# DISPC_L4_PER register map
Vendor: Texas Instruments
Registers are 32-bit, access per field, reset 0x0 unless marked. A register's access mark holds for its fields unless they carry their own. Offsets are as the file gives them; [hi:lo] are bit positions; {n}, {i} and the like mark numbered series; 'fields as' and 'values as' point back to an identical list.

## DISPC_L4_PER (part 5 of 5)
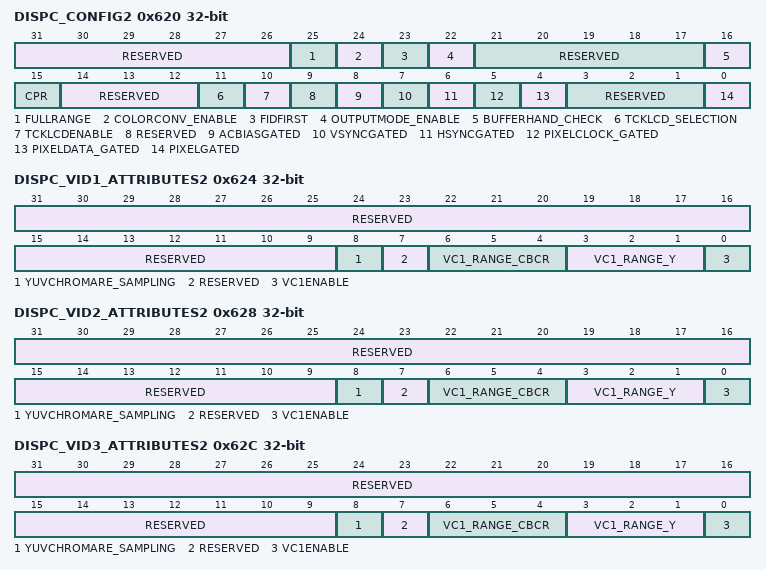
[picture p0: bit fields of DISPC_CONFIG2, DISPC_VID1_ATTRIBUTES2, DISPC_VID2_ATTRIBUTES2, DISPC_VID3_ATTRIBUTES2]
0x620 DISPC_CONFIG2 — The control register configures the Display Controller module for the secondary LCD output. Shadow register, updated on VFP start period of secondary LCD or EVSYNC
  [31:26] RESERVED ro — Write 0s for future compatibility. Reads return 0.
  [25] FULLRANGE rw — Color Space Conversion full range setting.
    0=Limited range selected; 1=Full range selected
  [24] COLORCONV_ENABLE rw — Enable the color space conversion. It shall be reset when CPR bit field is set to 0x1.
    0=Disable Color Space Conversion RGB to YUV; 1=Enable Color Space Conversion RGB to YUV
  [23] FIDFIRST rw — Selects the first field to output in case of interlace mode. In case of progressive mode, the value is not used.
    0=First field is even; 1=Odd field is first
  [22] OUTPUTMODE_ENABLE rw — Selects between progressive and interlace mode for the secondary LCD output.
    0=Progressive mode selected; 1=Interlace mode selected
  [21:17] RESERVED ro — Write 0s for future compatibility. Reads return 0.
  [16] BUFFERHAND_CHECK rw — Controls the handcheck between DMA buffer and STALL signal in order to prevent from underflow. The bit shall be set to 0 when the module is not in STALL mode. (secondary LCD output)
    0=Only the STALL signal (generated by RFBI or DSI2 depending on which IP uses the LCD output) is used regardless of the DMA buffer fullness information in order to provide data to the RFBI or DS2 module; 1=The STALL signal (generated by RFBI or DSI2 depending on which IP uses the LCD output) is used in combination with the DMA buffer fullness information in order to provide data to the RFBI or DSI2 module only when it does not generated buffer underflow
  [15] CPR rw — Color Phase Rotation Control secondary LCD output). It shall be reset when ColorConvEnable bit field is set to 1. wr: VFP start period of secondary LCD output
    0=Color Phase Rotation Disabled; 1=Color Phase Rotation Enabled
  [14:12] RESERVED ro — Write 0s for future compatibility. Reads return 0.
  [11] TCKLCD_SELECTION rw — Transparency Color Key Selection (secondary LCD output) wr: VFP start period of secondary LCD output
    0=Destination transparency color key selected; 1=Source transparency color key selected
  [10] TCKLCDENABLE rw — Transparency Color Key Enabled (secondary LCD output) wr: VFP start period of secondary LCD output
    0=Disable the transparency color key for the LCD; 1=Enable the transparency color key for the LCD
  [9] RESERVED ro — Write 0s for future compatibility. Reads return 0.
  [8] ACBIASGATED rw — ACBias Gated Enabled (secondary LCD output) wr: VFP start period of secondary LCD output
    0=AcBias Gated Disabled; 1=AcBias Gated Enabled
  [7] VSYNCGATED rw — VSYNC Gated Enabled (secondary LCD output) wr: VFP start period of secondary LCD output
    0=VSYNC Gated Disabled; 1=VSYNC Gated Enabled
  [6] HSYNCGATED rw — HSYNC Gated Enabled (secondary LCD output) wr: VFP start period of secondary LCD output
    0=HSYNC Gated Disabled; 1=HSYNC Gated Enabled
  [5] PIXELCLOCK_GATED rw — Pixel Clock Gated Enabled (secondary LCD output) wr: VFP start period of secondary LCD output
    0=Pixel Clock Gated Disabled; 1=Pixel Clock Gated Enabled
  [4] PIXELDATA_GATED rw — Pixel Data Gated Enabled (secondary LCD output) wr: VFP start period of secondary LCD output
    0=Pixel Data Gated Disabled; 1=Pixel Data Gated Enabled
  [3:1] RESERVED ro — Write 0s for future compatibility. Reads return 0.
  [0] PIXELGATED rw — Pixel Gated Enable (only for Active Matrix) (secondary LCD output) wr: VFP start period of secondary LCD output
    0=Pixel clock always toggles (only in Active Matrix mode); 1=Pixel clock only toggles when there is valid data to display. (only in Active Matrix mode)
0x624 DISPC_VID1_ATTRIBUTES2 — The register configures the attributes of the video window 1. Shadow register, updated on VFP start period of primary LCD or VFP start period of the secondary LCD or EVSYNC or when.GOWB is set to 1 by software and current WB frame is finished (no more data in the write-back pipeline). The synchronization event is defined based on the output using the pipeline: primary LCD, secondary LCD, TV output or write-back to the memory
  [31:9] RESERVED ro — Write 0s for future compatibility. Reads return 0.
  [8] YUVCHROMARE_SAMPLING rw — The YUV chrominance can be resampled using averaging of the adjacent chrominance samples, without using the polyphase filter for 4:2:2 input or can be calculated using the polyphase filter for 4:2:2/4:2:0. The polyphase filter is mandatory for the 4:2:0 format. This bit controls the order in which the processing is done on the video pipe.
    0=When input is 4:2:2, the missing chrominance samples are calculated by averaging the adjacent samples if. ROTATION=0 only. Other rotation configurations are not supported.; 1=For 4:2:2 (or 4:2:0), the missing chrominance samples are calculated by filtering the adjacent samples (5-tap polyphase filter). See, Configuration 2: Video Pipeline. All rotation configurations are supported.
  [7] RESERVED ro — Write 0s for future compatibility. Reads return 0.
  [6:4] VC1_RANGE_CBCR rw — Defines the VC-1 range value for the CbCr component from 0 to 7.
  [3:1] VC1_RANGE_Y rw — Defines the VC-1 range value for the Y component from 0 to 7.
  [0] VC1ENABLE rw — Enable/disable the VC-1 range mapping processing. The bit field is ignored if the format is not one of the supported YUV formats.
    0=VC-1 range mapping disabled; 1=VC-1 range mapping enabled
0x628 DISPC_VID2_ATTRIBUTES2 — The register configures the attributes of the video window 2. Shadow register, updated on VFP start period of primary LCD or VFP start period of the secondary LCD or EVSYNC or when.GOWB is set to 1 by software and current WB frame is finished (no more data in the write-back pipeline). The synchronization event is defined based on the output using the pipeline: primary LCD, secondary LCD, TV output or write-back to the memory
  [31:9] RESERVED ro — Write 0s for future compatibility. Reads return 0.
  [8] YUVCHROMARE_SAMPLING rw — The YUV chrominance can be resampled using averaging of the adjacent chrominance samples, without using the polyphase filter for 4:2:2 input or can be calculated using the polyphase filter for 4:2:2/4:2:0. The polyphase filter is mandatory for the 4:2:0 format. This bit controls the order in which the processing is done on the video pipe.
    0=When input is in 4:2:2, the missing chrominance samples are calculated by averaging the adjacent samples if. ROTATION=0 only. Other rotation configurations are not supported.; 1=For 4:2:2 (or 4:2:0), the missing chrominance samples are calculated by filtering the adjacent samples (5-tap polyphase filter). See, Configuration 2: Video Pipeline. All rotation configurations are supported.
  [7] RESERVED ro — Write 0s for future compatibility. Reads return 0.
  [6:4] VC1_RANGE_CBCR rw — Defines the VC-1 range value for the CbCr component from 0 to 7.
  [3:1] VC1_RANGE_Y rw — Defines the VC-1 range value for the Y component from 0 to 7.
  [0] VC1ENABLE rw — Enable/disable the VC-1 range mapping processing. The bit field is ignored if the format is not one of the supported YUV formats.
    0=VC-1 range mapping disabled; 1=VC-1 range mapping enabled
0x62C DISPC_VID3_ATTRIBUTES2 — The register configures the attributes of the video window 3. Shadow register, updated on VFP start period of primary LCD or VFP start period of the secondary LCD or EVSYNC or when.GOWB is set to 1 by software and current WB frame is finished (no more data in the write-back pipeline). The synchronization event is defined based on the output using the pipeline: primary LCD, secondary LCD, TV output or write-back to the memory
  fields as DISPC_VID2_ATTRIBUTES2
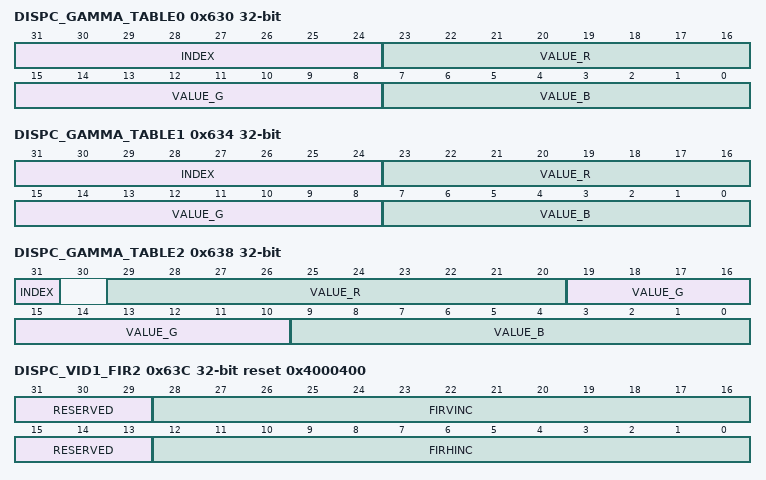
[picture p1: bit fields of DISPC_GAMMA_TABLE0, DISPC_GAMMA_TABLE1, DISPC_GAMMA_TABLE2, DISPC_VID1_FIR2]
0x630 DISPC_GAMMA_TABLE0 wo — The register configures the look up table used as color look up table for BITMAP formats (1-, 2-, 4, and 8-bpp) on the graphics pipeline or as gamma table on the primary LCD output.
  [31:24] INDEX — Defines the location in the table where the bit field VALUE is stored.
  [23:16] VALUE_R — 8-bit value used to defined the value to store at the location in the table defined by the bit field INDEX.
  [15:8] VALUE_G — 8-bit value used to defined the value to store at the location in the table defined by the bit field INDEX.
  [7:0] VALUE_B — 8-bit value used to defined the value to store at the location in the table defined by the bit field INDEX.
0x634 DISPC_GAMMA_TABLE1 wo — The register configures the gamma table on the secondary LCD output.
  fields as DISPC_GAMMA_TABLE0
0x638 DISPC_GAMMA_TABLE2 wo — The register configures the gamma table on the TV output.
  [31] INDEX — Setting this bit to 1 resets the internal index counter to zero. Each subsequent access to the register (with the INDEX bit kept at 0) increments the address for the next storage location into the table memory.
  [29:20] VALUE_R — 10-bit color component value to store in the table.
  [19:10] VALUE_G — 10-bit color component value to store in the table.
  [9:0] VALUE_B — 10-bit color component value to store in the table.
0x63C DISPC_VID1_FIR2 reset 0x4000400 — The register configures the resize factors for horizontal and vertical up/downsampling of the video window 1. It is used for Crb and Cr setting. It is used only when the pixel format at the input of the filter is one of the YUV formats. If the pixel format at the input of the filter is ARGB (all ARGB, RGB, RGBA are converted to ARGB32-8888 by the color space conversion before going to the filter is the color space conversion is done before the filter). When the register is not used by the hardware, any value can be used for the bit fields. Shadow register, updated on VFP start period of primary LCD or VFP start period of the secondary LCD or EVSYNC or when.GOWB is set to 1 by software and current WB frame is finished (no more data in the write-back pipeline). The synchronization event is defined based on the output using the pipeline: primary LCD, secondary LCD, TV output or write-back to the memory
  [31:29] RESERVED ro — Write 0s for future compatibility. Reads return 0.
  [28:16] FIRVINC rw — Vertical increment of the up/downsampling filter for Cb and Cr. Encoded value (from 1 to 4096). The value 0 is invalid. The values greater than 4096 are invalid.
  [15:13] RESERVED ro — Write 0s for future compatibility. Reads return 0.
  [12:0] FIRHINC rw — Horizontal increment of the up/downsampling filter for Cb and Cr. Encoded value (from 1 to 4096). The value 0 is invalid. The values greater than 4096 are invalid.
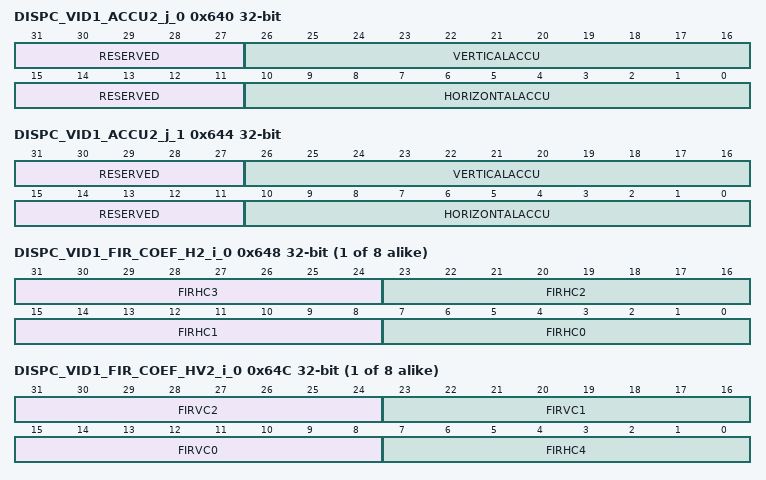
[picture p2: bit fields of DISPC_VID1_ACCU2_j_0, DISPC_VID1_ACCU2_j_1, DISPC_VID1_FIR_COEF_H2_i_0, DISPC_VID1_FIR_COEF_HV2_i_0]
0x640 DISPC_VID1_ACCU2_j_0 — The register configures the resize accumulator init values for horizontal and vertical up/downsampling of the video window 1 (DISPC_VID1_ACCU2_0 and DISPC_VID1_ACCU2_1 for ping-pong mechanism with external trigger, based on the field polarity) It is used for Cb and Cr setting. It is used only when the pixel format at the input of the filter is one of the YUV formats. If the pixel format at the input of the filter is ARGB (all ARGB, RGB, RGBA are converted to ARGB32-8888 by the color space conversion before going to the filter is the color space conversion is done before the filter). When the register is not used by the hardware, any value can be used for the bit fields. Shadow register, updated on VFP start period of primary LCD or VFP start period of the secondary LCD or EVSYNC or when.GOWB is set to 1 by software and current WB frame is finished (no more data in the write-back pipeline). The synchronization event is defined based on the output using the pipeline: primary LCD, secondary LCD, TV output or write-back to the memory
  [31:27] RESERVED ro — Write 0s for future compatibility. Reads return 0.
  [26:16] VERTICALACCU rw — Vertical initialization accu value Encoded value (from -1024 to 1023).
  [15:11] RESERVED ro — Write 0s for future compatibility. Reads return 0.
  [10:0] HORIZONTALACCU rw — Horizontal initialization accu value Encoded value (from -1024 to 1023).
0x644 DISPC_VID1_ACCU2_j_1 — The register configures the resize accumulator init values for horizontal and vertical up/downsampling of the video window 1 (DISPC_VID1_ACCU2_0 and DISPC_VID1_ACCU2_1 for ping-pong mechanism with external trigger, based on the field polarity) It is used for Cb and Cr setting. It is used only when the pixel format at the input of the filter is one of the YUV formats. If the pixel format at the input of the filter is ARGB (all ARGB, RGB, RGBA are converted to ARGB32-8888 by the color space conversion before going to the filter is the color space conversion is done before the filter). When the register is not used by the hardware, any value can be used for the bit fields. Shadow register, updated on VFP start period of primary LCD or VFP start period of the secondary LCD or EVSYNC or when.GOWB is set to 1 by software and current WB frame is finished (no more data in the write-back pipeline). The synchronization event is defined based on the output using the pipeline: primary LCD, secondary LCD, TV output or write-back to the memory
  fields as DISPC_VID1_ACCU2_j_0
{0x648+8i} DISPC_VID1_FIR_COEF_H2_i_{i} rw (i=0..7) — The bank of registers configure the up/down-scaling coefficients for the horizontal resize of the video picture associated with the video window 1 for the phases from 0 to 7. It is used for Crb and Cr setting. It is used only when the pixel format at the input of the filter is one of the YUV formats. If the pixel format at the input of the filter is ARGB (all ARGB, RGB, RGBA are converted to ARGB32-8888 by the color space conversion before going to the filter is the color space conversion is done before the filter). When the register is not used by the hardware, any value can be used for the bit fields. Shadow register, updated on VFP start period of primary LCD or VFP start period of the secondary LCD or EVSYNC or when.GOWB is set to 1 by software and current WB frame is finished (no more data in the write-back pipeline). The synchronization event is defined based on the output using the pipeline: primary LCD, secondary LCD, TV output or write-back to the memory
  [31:24] FIRHC3 — Signed coefficient C3 for the horizontal up/down-scaling with the phase n
  [23:16] FIRHC2 — Unsigned coefficient C2 for the horizontal up/down-scaling with the phase n
  [15:8] FIRHC1 — Signed coefficient C1 for the horizontal up/down-scaling with the phase n
  [7:0] FIRHC0 — Signed coefficient C0 for the horizontal up/down-scaling with the phase n
{0x64C+8i} DISPC_VID1_FIR_COEF_HV2_i_{i} rw (i=0..7) — The bank of registers configure the down/up/down-scaling coefficients for the vertical and horizontal resize of the video picture associated with the video window 1 for the phases from 0 to 7. It is used for Crb and Cr setting. It is used only when the pixel format at the input of the filter is one of the YUV formats. If the pixel format at the input of the filter is ARGB (all ARGB, RGB, RGBA are converted to ARGB32-8888 by the color space conversion before going to the filter is the color space conversion is done before the filter). When the register is not used by the hardware, any value can be used for the bit fields. Shadow register, updated on VFP start period of primary LCD or VFP start period of the secondary LCD or EVSYNC or when.GOWB is set to 1 by software and current WB frame is finished (no more data in the write-back pipeline). The synchronization event is defined based on the output using the pipeline: primary LCD, secondary LCD, TV output or write-back to the memory
  [31:24] FIRVC2 — Signed coefficient C2 for the vertical up/down-scaling with the phase n
  [23:16] FIRVC1 — Unsigned coefficient C1 for the vertical up/down-scaling with the phase n
  [15:8] FIRVC0 — Signed coefficient C0 for the vertical up/down-scaling with the phase n
  [7:0] FIRHC4 — Signed coefficient C4 for the horizontal up/down-scaling with the phase n
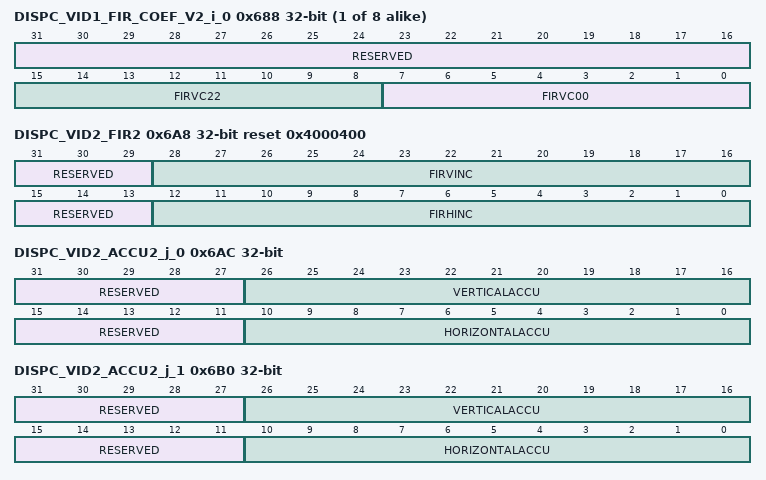
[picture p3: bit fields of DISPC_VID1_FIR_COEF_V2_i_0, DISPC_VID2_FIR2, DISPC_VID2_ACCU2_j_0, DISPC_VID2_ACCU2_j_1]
{0x688+4i} DISPC_VID1_FIR_COEF_V2_i_{i} (i=0..7) — The bank of registers configure the down/up/down-scaling coefficients for the vertical resize of the video picture associated with the video window 1 for the phases from 0 to 7. It is used for Crb and Cr setting. It is used only when the pixel format at the input of the filter is one of the YUV formats. If the pixel format at the input of the filter is ARGB (all ARGB, RGB, RGBA are converted to ARGB32-8888 by the color space conversion before going to the filter is the color space conversion is done before the filter). When the register is not used by the hardware, any value can be used for the bit fields. Shadow register, updated on VFP start period of primary LCD or VFP start period of the secondary LCD or EVSYNC or when.GOWB is set to 1 by software and current WB frame is finished (no more data in the write-back pipeline). The synchronization event is defined based on the output using the pipeline: primary LCD, secondary LCD, TV output or write-back to the memory
  [31:16] RESERVED ro — Write 0s for future compatibility. Reads return 0.
  [15:8] FIRVC22 rw — Signed coefficient C22 for the vertical up/down-scaling with the phase n
  [7:0] FIRVC00 rw — Signed coefficient C00 for the vertical up/down-scaling with the phase n
0x6A8 DISPC_VID2_FIR2 reset 0x4000400 — The register configures the resize factors for horizontal and vertical up/downsampling of the video window 2. It is used for Crb and Cr setting. It is used only when the pixel format at the input of the filter is one of the YUV formats. If the pixel format at the input of the filter is ARGB (all ARGB, RGB, RGBA are converted to ARGB32-8888 by the color space conversion before going to the filter is the color space conversion is done before the filter). When the register is not used by the hardware, any value can be used for the bit fields. Shadow register, updated on VFP start period of primary LCD or VFP start period of the secondary LCD or EVSYNC or when.GOWB is set to 1 by software and current WB frame is finished (no more data in the write-back pipeline). The synchronization event is defined based on the output using the pipeline: primary LCD, secondary LCD, TV output or write-back to the memory
  fields as DISPC_VID1_FIR2
0x6AC DISPC_VID2_ACCU2_j_0 — The register configures the resize accumulator init values for horizontal and vertical up/downsampling of the video window 2 (DISPC_VID2_ACCU2_0 and DISPC_VID2_ACCU2_1 for ping-pong mechanism with external trigger, based on the field polarity). It is used for Cb and Cr setting. It is used only when the pixel format at the input of the filter is one of the YUV formats. If the pixel format at the input of the filter is ARGB (all ARGB, RGB, RGBA are converted to ARGB32-8888 by the color space conversion before going to the filter is the color space conversion is done before the filter). When the register is not used by the hardware, any value can be used for the bit fields. Shadow register, updated on VFP start period of primary LCD or VFP start period of the secondary LCD or EVSYNC or when.GOWB is set to 1 by software and current WB frame is finished (no more data in the write-back pipeline). The synchronization event is defined based on the output using the pipeline: primary LCD, secondary LCD, TV output or write-back to the memory
  fields as DISPC_VID1_ACCU2_j_0
0x6B0 DISPC_VID2_ACCU2_j_1 — The register configures the resize accumulator init values for horizontal and vertical up/downsampling of the video window 2 (DISPC_VID2_ACCU2_0 and DISPC_VID2_ACCU2_1 for ping-pong mechanism with external trigger, based on the field polarity). It is used for Cb and Cr setting. It is used only when the pixel format at the input of the filter is one of the YUV formats. If the pixel format at the input of the filter is ARGB (all ARGB, RGB, RGBA are converted to ARGB32-8888 by the color space conversion before going to the filter is the color space conversion is done before the filter). When the register is not used by the hardware, any value can be used for the bit fields. Shadow register, updated on VFP start period of primary LCD or VFP start period of the secondary LCD or EVSYNC or when.GOWB is set to 1 by software and current WB frame is finished (no more data in the write-back pipeline). The synchronization event is defined based on the output using the pipeline: primary LCD, secondary LCD, TV output or write-back to the memory
  fields as DISPC_VID1_ACCU2_j_0
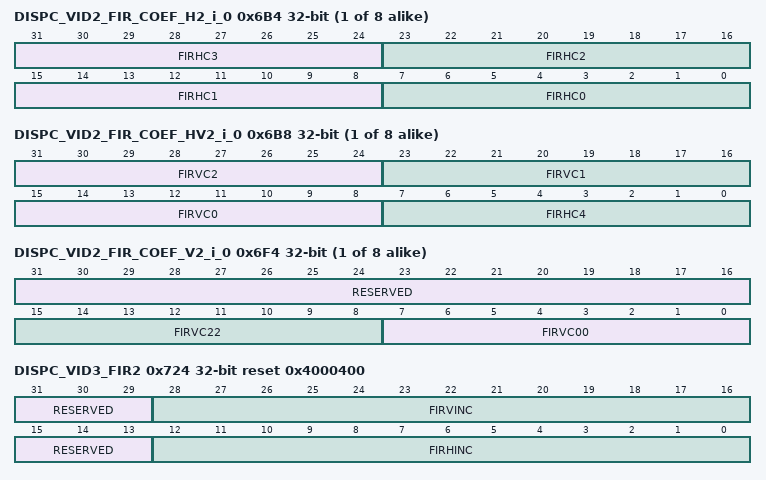
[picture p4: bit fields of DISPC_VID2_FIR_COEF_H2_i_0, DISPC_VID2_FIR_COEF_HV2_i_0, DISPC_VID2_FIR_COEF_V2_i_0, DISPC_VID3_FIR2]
{0x6B4+8i} DISPC_VID2_FIR_COEF_H2_i_{i} rw (i=0..7) — The bank of registers configure the up/down-scaling coefficients for the horizontal resize of the video picture associated with the video window 2 for the phases from 0 to 7. It is used for Crb and Cr setting. It is used only when the pixel format at the input of the filter is one of the YUV formats. If the pixel format at the input of the filter is ARGB (all ARGB, RGB, RGBA are converted to ARGB32-8888 by the color space conversion before going to the filter is the color space conversion is done before the filter). When the register is not used by the hardware, any value can be used for the bit fields. Shadow register, updated on VFP start period of primary LCD or VFP start period of the secondary LCD or EVSYNC or when.GOWB is set to 1 by software and current WB frame is finished (no more data in the write-back pipeline). The synchronization event is defined based on the output using the pipeline: primary LCD, secondary LCD, TV output or write-back to the memory
  fields as DISPC_VID1_FIR_COEF_H2_i_0
{0x6B8+8i} DISPC_VID2_FIR_COEF_HV2_i_{i} rw (i=0..7) — The bank of registers configure the down/up/down-scaling coefficients for the vertical and horizontal resize of the video picture associated with the video window 2 for the phases from 0 to 7. It is used for Crb and Cr setting. It is used only when the pixel format at the input of the filter is one of the YUV formats. If the pixel format at the input of the filter is ARGB (all ARGB, RGB, RGBA are converted to ARGB32-8888 by the color space conversion before going to the filter is the color space conversion is done before the filter). When the register is not used by the hardware, any value can be used for the bit fields. Shadow register, updated on VFP start period of primary LCD or VFP start period of the secondary LCD or EVSYNC or when.GOWB is set to 1 by software and current WB frame is finished (no more data in the write-back pipeline). The synchronization event is defined based on the output using the pipeline: primary LCD, secondary LCD, TV output or write-back to the memory
  fields as DISPC_VID1_FIR_COEF_HV2_i_0
{0x6F4+4i} DISPC_VID2_FIR_COEF_V2_i_{i} (i=0..7) — The bank of registers configure the down/up/down-scaling coefficients for the vertical resize of the video picture associated with the video window 2 for the phases from 0 to 7. It is used for Crb and Cr setting. It is used only when the pixel format at the input of the filter is one of the YUV formats. If the pixel format at the input of the filter is ARGB (all ARGB, RGB, RGBA are converted to ARGB32-8888 by the color space conversion before going to the filter is the color space conversion is done before the filter). When the register is not used by the hardware, any value can be used for the bit fields. Shadow register, updated on VFP start period of primary LCD or VFP start period of the secondary LCD or EVSYNC or when.GOWB is set to 1 by software and current WB frame is finished (no more data in the write-back pipeline). The synchronization event is defined based on the output using the pipeline: primary LCD, secondary LCD, TV output or write-back to the memory
  fields as DISPC_VID1_FIR_COEF_V2_i_0
0x724 DISPC_VID3_FIR2 reset 0x4000400 — The register configures the resize factors for horizontal and vertical up/downsampling of the video window 3. It is used for Crb and Cr setting. It is used only when the pixel format at the input of the filter is one of the YUV formats. If the pixel format at the input of the filter is ARGB (all ARGB, RGB, RGBA are converted to ARGB32-8888 by the color space conversion before going to the filter is the color space conversion is done before the filter). When the register is not used by the hardware, any value can be used for the bit fields. Shadow register, updated on VFP start period of primary LCD or VFP start period of the secondary LCD or EVSYNC or when.GOWB is set to 1 by software and current WB frame is finished (no more data in the write-back pipeline). The synchronization event is defined based on the output using the pipeline: primary LCD, secondary LCD, TV output or write-back to the memory
  fields as DISPC_VID1_FIR2
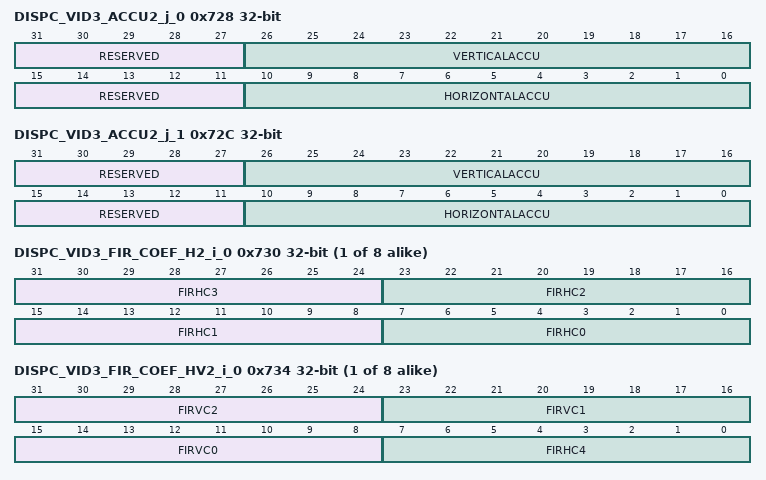
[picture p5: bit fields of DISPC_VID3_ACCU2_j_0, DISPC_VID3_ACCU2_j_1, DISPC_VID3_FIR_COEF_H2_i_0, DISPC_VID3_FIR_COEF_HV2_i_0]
0x728 DISPC_VID3_ACCU2_j_0 — The register configures the resize accumulator init values for horizontal and vertical up/downsampling of the video window 3 (DISPC_VID3_ACCU2_0 and DISPC_VID3_ACCU2_1 for ping-pong mechanism with external trigger, based on the field polarity). It is used for Cb and Cr setting. It is used only when the pixel format at the input of the filter is one of the YUV formats. If the pixel format at the input of the filter is ARGB (all ARGB, RGB, RGBA are converted to ARGB32-8888 by the color space conversion before going to the filter is the color space conversion is done before the filter). When the register is not used by the hardware, any value can be used for the bit fields. Shadow register, updated on VFP start period of primary LCD or VFP start period of the secondary LCD or EVSYNC or when.GOWB is set to 1 by software and current WB frame is finished (no more data in the write-back pipeline). The synchronization event is defined based on the output using the pipeline: primary LCD, secondary LCD, TV output or write-back to the memory
  fields as DISPC_VID1_ACCU2_j_0
0x72C DISPC_VID3_ACCU2_j_1 — The register configures the resize accumulator init values for horizontal and vertical up/downsampling of the video window 3 (DISPC_VID3_ACCU2_0 and DISPC_VID3_ACCU2_1 for ping-pong mechanism with external trigger, based on the field polarity). It is used for Cb and Cr setting. It is used only when the pixel format at the input of the filter is one of the YUV formats. If the pixel format at the input of the filter is ARGB (all ARGB, RGB, RGBA are converted to ARGB32-8888 by the color space conversion before going to the filter is the color space conversion is done before the filter). When the register is not used by the hardware, any value can be used for the bit fields. Shadow register, updated on VFP start period of primary LCD or VFP start period of the secondary LCD or EVSYNC or when.GOWB is set to 1 by software and current WB frame is finished (no more data in the write-back pipeline). The synchronization event is defined based on the output using the pipeline: primary LCD, secondary LCD, TV output or write-back to the memory
  fields as DISPC_VID1_ACCU2_j_0
{0x730+8i} DISPC_VID3_FIR_COEF_H2_i_{i} rw (i=0..7) — The bank of registers configure the up/down-scaling coefficients for the horizontal resize of the video picture associated with the video window 3 for the phases from 0 to 7. It is used for Crb and Cr setting. It is used only when the pixel format at the input of the filter is one of the YUV formats. If the pixel format at the input of the filter is ARGB (all ARGB, RGB, RGBA are converted to ARGB32-8888 by the color space conversion before going to the filter is the color space conversion is done before the filter). When the register is not used by the hardware, any value can be used for the bit fields. Shadow register, updated on VFP start period of primary LCD or VFP start period of the secondary LCD or EVSYNC or when.GOWB is set to 1 by software and current WB frame is finished (no more data in the write-back pipeline). The synchronization event is defined based on the output using the pipeline: primary LCD, secondary LCD, TV output or write-back to the memory
  fields as DISPC_VID1_FIR_COEF_H2_i_0
{0x734+8i} DISPC_VID3_FIR_COEF_HV2_i_{i} rw (i=0..7) — The bank of registers configure the down/up/down-scaling coefficients for the vertical and horizontal resize of the video picture associated with the video window 3 for the phases from 0 to 7. It is used for Crb and Cr setting. It is used only when the pixel format at the input of the filter is one of the YUV formats. If the pixel format at the input of the filter is ARGB (all ARGB, RGB, RGBA are converted to ARGB32-8888 by the color space conversion before going to the filter is the color space conversion is done before the filter). When the register is not used by the hardware, any value can be used for the bit fields. Shadow register, updated on VFP start period of primary LCD or VFP start period of the secondary LCD or EVSYNC or when.GOWB is set to 1 by software and current WB frame is finished (no more data in the write-back pipeline). The synchronization event is defined based on the output using the pipeline: primary LCD, secondary LCD, TV output or write-back to the memory
  fields as DISPC_VID1_FIR_COEF_HV2_i_0
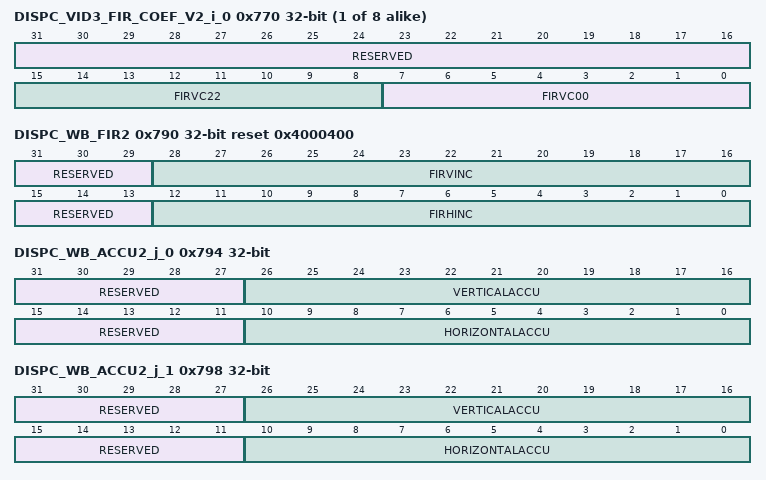
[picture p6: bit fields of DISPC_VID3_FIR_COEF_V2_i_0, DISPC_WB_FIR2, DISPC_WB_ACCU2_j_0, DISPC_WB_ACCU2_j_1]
{0x770+4i} DISPC_VID3_FIR_COEF_V2_i_{i} (i=0..7) — The bank of registers configure the down/up/down-scaling coefficients for the vertical resize of the video picture associated with the video window 3 for the phases from 0 to 7. It is used for Crb and Cr setting. It is used only when the pixel format at the input of the filter is one of the YUV formats. If the pixel format at the input of the filter is ARGB (all ARGB, RGB, RGBA are converted to ARGB32-8888 by the color space conversion before going to the filter is the color space conversion is done before the filter). When the register is not used by the hardware, any value can be used for the bit fields. Shadow register, updated on VFP start period of primary LCD or VFP start period of the secondary LCD or EVSYNC or when.GOWB is set to 1 by software and current WB frame is finished (no more data in the write-back pipeline). The synchronization event is defined based on the output using the pipeline: primary LCD, secondary LCD, TV output or write-back to the memory
  fields as DISPC_VID1_FIR_COEF_V2_i_0
0x790 DISPC_WB_FIR2 reset 0x4000400 — The register configures the resize factors for horizontal and vertical up/downsampling of the write-back pipeline. It is used for Crb and Cr setting. It is used only when the pixel format at the input of the filter is one of the YUV formats. If the pixel format at the input of the filter is ARGB (all ARGB, RGB, RGBA are converted to ARGB32-8888 by the color space conversion before going to the filter is the color space conversion is done before the filter). When the register is not used by the hardware, any value can be used for the bit fields. Shadow register, updated when.GOWB is set to 1 by software and current WB frame is finished (no more data in the write-back pipeline) when the WB pipeline is directly connected to one of the pipelines (graphics or video), otherwise updated on VFP start period of primary LCD or VFP start period of secondary LCD or EVSYNC depending on which overlay output is selected as an input to the WB pipeline
  fields as DISPC_VID1_FIR2
0x794 DISPC_WB_ACCU2_j_0 — The register configures the resize accumulator init values for horizontal and vertical up/downsampling of the write back pipeline (DISPC_WB_ACCU2_0 and DISPC_WB_ACCU2_1 for ping-pong mechanism with external trigger, based on the field polarity). It is used for Cb and Cr setting. It is used only when the pixel format at the input of the filter is one of the YUV formats. If the pixel format at the input of the filter is ARGB (all ARGB, RGB, RGBA are converted to ARGB32-8888 by the color space conversion before going to the filter is the color space conversion is done before the filter). When the register is not used by the hardware, any value can be used for the bit fields. Shadow register, updated when.GOWB is set to 1 by software and current WB frame is finished (no more data in the write-back pipeline) when the WB pipeline is directly connected to one of the pipelines (graphics or video), otherwise updated on VFP start period of primary LCD or VFP start period of secondary LCD or EVSYNC depending on which overlay output is selected as an input to the WB pipeline
  fields as DISPC_VID1_ACCU2_j_0
0x798 DISPC_WB_ACCU2_j_1 — The register configures the resize accumulator init values for horizontal and vertical up/downsampling of the write back pipeline (DISPC_WB_ACCU2_0 and DISPC_WB_ACCU2_1 for ping-pong mechanism with external trigger, based on the field polarity). It is used for Cb and Cr setting. It is used only when the pixel format at the input of the filter is one of the YUV formats. If the pixel format at the input of the filter is ARGB (all ARGB, RGB, RGBA are converted to ARGB32-8888 by the color space conversion before going to the filter is the color space conversion is done before the filter). When the register is not used by the hardware, any value can be used for the bit fields. Shadow register, updated when.GOWB is set to 1 by software and current WB frame is finished (no more data in the write-back pipeline) when the WB pipeline is directly connected to one of the pipelines (graphics or video), otherwise updated on VFP start period of primary LCD or VFP start period of secondary LCD or EVSYNC depending on which overlay output is selected as an input to the WB pipeline
  fields as DISPC_VID1_ACCU2_j_0
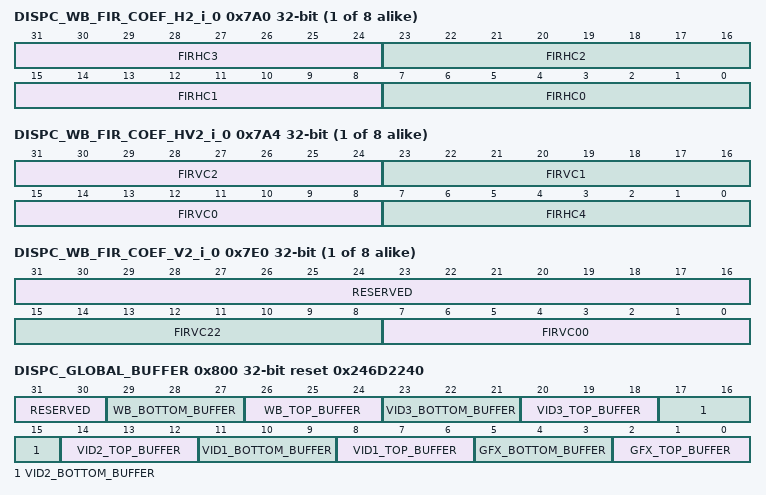
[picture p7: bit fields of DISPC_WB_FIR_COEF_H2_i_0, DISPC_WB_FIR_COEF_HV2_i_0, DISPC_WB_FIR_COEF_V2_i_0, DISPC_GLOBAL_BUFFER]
{0x7A0+8i} DISPC_WB_FIR_COEF_H2_i_{i} rw (i=0..7) — The bank of registers configure the up/down-scaling coefficients for the horizontal resize of the video picture associated with the write back pipeline for the phases from 0 to 7. It is used for Crb and Cr setting. It is used only when the pixel format at the input of the filter is one of the YUV formats. If the pixel format at the input of the filter is ARGB (all ARGB, RGB, RGBA are converted to ARGB32-8888 by the color space conversion before going to the filter is the color space conversion is done before the filter). When the register is not used by the hardware, any value can be used for the bit fields. Shadow register, updated when.GOWB is set to 1 by software and current WB frame is finished (no more data in the write-back pipeline) when the WB pipeline is directly connected to one of the pipelines (graphics or video), otherwise updated on VFP start period of primary LCD or VFP start period of secondary LCD or EVSYNC depending on which overlay output is selected as an input to the WB pipeline
  fields as DISPC_VID1_FIR_COEF_H2_i_0
{0x7A4+8i} DISPC_WB_FIR_COEF_HV2_i_{i} rw (i=0..7) — The bank of registers configure the down/up/down-scaling coefficients for the vertical and horizontal resize of the video picture associated with the write back pipeline for the phases from 0 to 7. It is used for Crb and Cr setting. It is used only when the pixel format at the input of the filter is one of the YUV formats. If the pixel format at the input of the filter is ARGB (all ARGB, RGB, RGBA are converted to ARGB32-8888 by the color space conversion before going to the filter is the color space conversion is done before the filter). When the register is not used by the hardware, any value can be used for the bit fields. Shadow register, updated when.GOWB is set to 1 by software and current WB frame is finished (no more data in the write-back pipeline) when the WB pipeline is directly connected to one of the pipelines (graphics or video), otherwise updated on VFP start period of primary LCD or VFP start period of secondary LCD or EVSYNC depending on which overlay output is selected as an input to the WB pipeline
  fields as DISPC_VID1_FIR_COEF_HV2_i_0
{0x7E0+4i} DISPC_WB_FIR_COEF_V2_i_{i} (i=0..7) — The bank of registers configure the down/up/down-scaling coefficients for the vertical resize of the video picture associated with the write back pipeline for the phases from 0 to 7. It is used for Crb and Cr setting. It is used only when the pixel format at the input of the filter is one of the YUV formats. If the pixel format at the input of the filter is ARGB (all ARGB, RGB, RGBA are converted to ARGB32-8888 by the color space conversion before going to the filter is the color space conversion is done before the filter). When the register is not used by the hardware, any value can be used for the bit fields. Shadow register, updated when.GOWB is set to 1 by software and current WB frame is finished (no more data in the write-back pipeline) when the WB pipeline is directly connected to one of the pipelines (graphics or video), otherwise updated on VFP start period of primary LCD or VFP start period of secondary LCD or EVSYNC depending on which overlay output is selected as an input to the WB pipeline
  fields as DISPC_VID1_FIR_COEF_V2_i_0
0x800 DISPC_GLOBAL_BUFFER reset 0x246D2240 — The register configures the DMA buffers allocations to the pipeline (graphics, video1, video2, video3 and write-back). Both TOP and BOTTOM must be allocated to the same pipeline.
  [31:30] RESERVED ro — Write 0s for future compatibility. Reads return 0.
  [29:27] WB_BOTTOM_BUFFER rw — Write-back DMA BOTTOM buffer (half of the full DMA buffer) allocation to one of the pipelines. By default to write-back pipeline.
    0=DMA buffer allocated to the graphics pipeline; 1=DMA buffer allocated to the video1 pipeline; 2=DMA buffer allocated to the vdieo2 pipeline; 3=DMA buffer allocated to the vdieo3 pipeline; 4=DMA buffer allocated to the write-back pipeline
  [26:24] WB_TOP_BUFFER rw — Write-back DMA TOP buffer (half of the full DMA buffer) allocation to one of the pipelines. By default to write-back pipeline.
    values as WB_BOTTOM_BUFFER
  [23:21] VID3_BOTTOM_BUFFER rw — Video3 DMA BOTTOM buffer (half of the full DMA buffer) allocation to one of the pipelines. By default to video3 pipeline.
    values as WB_BOTTOM_BUFFER
  [20:18] VID3_TOP_BUFFER rw — Video3 DMA TOP buffer (half of the full DMA buffer) allocation to one of the pipelines. By default to video3 pipeline.
    values as WB_BOTTOM_BUFFER
  [17:15] VID2_BOTTOM_BUFFER rw — Video2 DMA BOTTOM buffer (half of the full DMA buffer) allocation to one of the pipelines. By default to video2 pipeline.
    values as WB_BOTTOM_BUFFER
  [14:12] VID2_TOP_BUFFER rw — Video2 DMA TOP buffer (half of the full DMA buffer) allocation to one of the pipelines. By default to video2 pipeline.
    values as WB_BOTTOM_BUFFER
  [11:9] VID1_BOTTOM_BUFFER rw — Video1 DMA BOTTOM buffer (half of the full DMA buffer) allocation to one of the pipelines. By default to video1 pipeline.
    values as WB_BOTTOM_BUFFER
  [8:6] VID1_TOP_BUFFER rw — Video1 DMA TOP buffer (half of the full DMA buffer) allocation to one of the pipelines. By default to video 1 pipeline.
    values as WB_BOTTOM_BUFFER
  [5:3] GFX_BOTTOM_BUFFER rw — Graphics DMA BOTTOM buffer (half of the full DMA buffer) allocation to one of the pipelines. By default to graphics pipeline.
    values as WB_BOTTOM_BUFFER
  [2:0] GFX_TOP_BUFFER rw — Graphics DMA TOP buffer (half of the full DMA buffer) allocation to one of the pipelines. By default to graphics pipeline.
    values as WB_BOTTOM_BUFFER
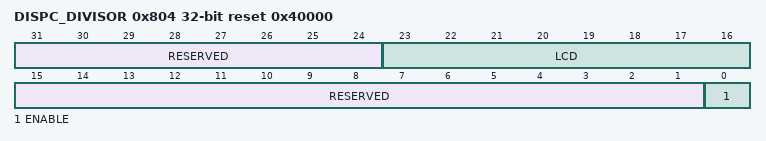
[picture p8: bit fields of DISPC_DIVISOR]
0x804 DISPC_DIVISOR reset 0x40000 — The register configures the divisor value for generating the core functional clock. There is a backward compatibility mode enabled by default in order to use.LCD value instead of .LCD bit field for generating the core functional clock.
  [31:24] RESERVED ro — Write 0s for future compatibility. Reads return 0.
  [23:16] LCD rw — Display Controller Logic Clock Divisor Value (from 1 to 255) to specify the frequency of the Display Controller logic clock based on the function clock. The value 0 is invalid.
  [15:1] RESERVED ro — Write 0s for future compatibility. Reads return 0.
  [0] ENABLE rw — When the bit field is set to 1, the bit field LCD is used to generated the core functional clock from the input clock. When the bit field is set to 0, the valueDISPC_DIVISOR1.LCD is used instead.
    0=.LCD bit field is used; 1=.LCD bit field is used
0x810 DISPC_WB_ATTRIBUTES2 — The register set the counter to control the delay to flush the WB pipe after the end of the frame in capture mode. Shadow register, updated on VFP start period of primary LCD or VFP start period of secondary LCD or EVSYNC depending on which overlay output is selected as an input to the WB pipeline
  [7:0] WBDELAYCOUNT rw — Delays the WB pipe flush after the end of the frame.delay = n x (1/F_clk) n = 0:255
